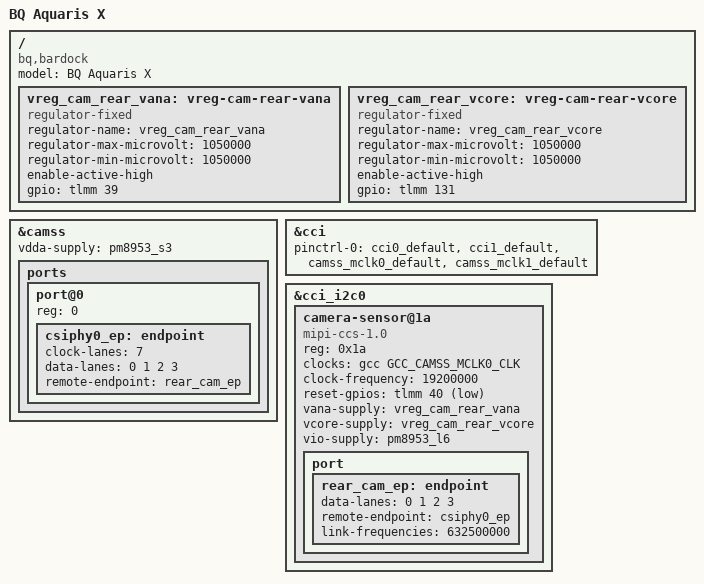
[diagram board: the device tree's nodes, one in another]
// SPDX-License-Identifier: BSD-3-Clause
/*
 * MSM8953 BQ Aquaris X specific device tree
 *
 * Copyright (c) 2023, Jens Reidel <adrian@travitia.xyz>
 */

/dts-v1/;

#include "msm8953-bq-common.dtsi"

/ {
	/*
	 * BQ Aquaris X
	 */
	model = "BQ Aquaris X";
	compatible = "bq,bardock", "qcom,msm8953";

	vreg_cam_rear_vana: vreg-cam-rear-vana {
		compatible = "regulator-fixed";
		regulator-name = "vreg_cam_rear_vana";
		regulator-max-microvolt = <1050000>;
		regulator-min-microvolt = <1050000>;
		enable-active-high;
		gpio = <&tlmm 39 GPIO_ACTIVE_HIGH>;
	};

	vreg_cam_rear_vcore: vreg-cam-rear-vcore {
		compatible = "regulator-fixed";
		regulator-name = "vreg_cam_rear_vcore";
		regulator-max-microvolt = <1050000>;
		regulator-min-microvolt = <1050000>;
		enable-active-high;
		gpio = <&tlmm 131 GPIO_ACTIVE_HIGH>;
	};
};

/* S5K4H8 is 8 MP */

&camss {
	status = "okay";
	vdda-supply = <&pm8953_s3>;

	ports {
		port@0 {
			reg = <0>;
			csiphy0_ep: endpoint {
				clock-lanes = <7>;
				data-lanes = <0 1 2 3>;
				remote-endpoint = <&rear_cam_ep>;
			};
		};
	};
};

&cci {
	pinctrl-names = "default";
	pinctrl-0 = <&cci0_default>,
		    <&cci1_default>,
		    <&camss_mclk0_default>,
		    <&camss_mclk1_default>;

	status = "okay";
};

&cci_i2c0 {
	camera-sensor@1a { // Rear camera, IMX298
		compatible = "mipi-ccs-1.0", "mipi-ccs";

		reg = <0x1a>;

		clocks = <&gcc GCC_CAMSS_MCLK0_CLK>;
		clock-frequency = <19200000>;

		reset-gpios = <&tlmm 40 GPIO_ACTIVE_LOW>;

		vana-supply = <&vreg_cam_rear_vana>;
		vcore-supply = <&vreg_cam_rear_vcore>;
		vio-supply = <&pm8953_l6>;

		status = "okay";

		port {
			rear_cam_ep: endpoint {
				data-lanes = <0 1 2 3>;
				remote-endpoint = <&csiphy0_ep>;
				link-frequencies = /bits/ 64 <632500000>;
			};
		};
	};
};
